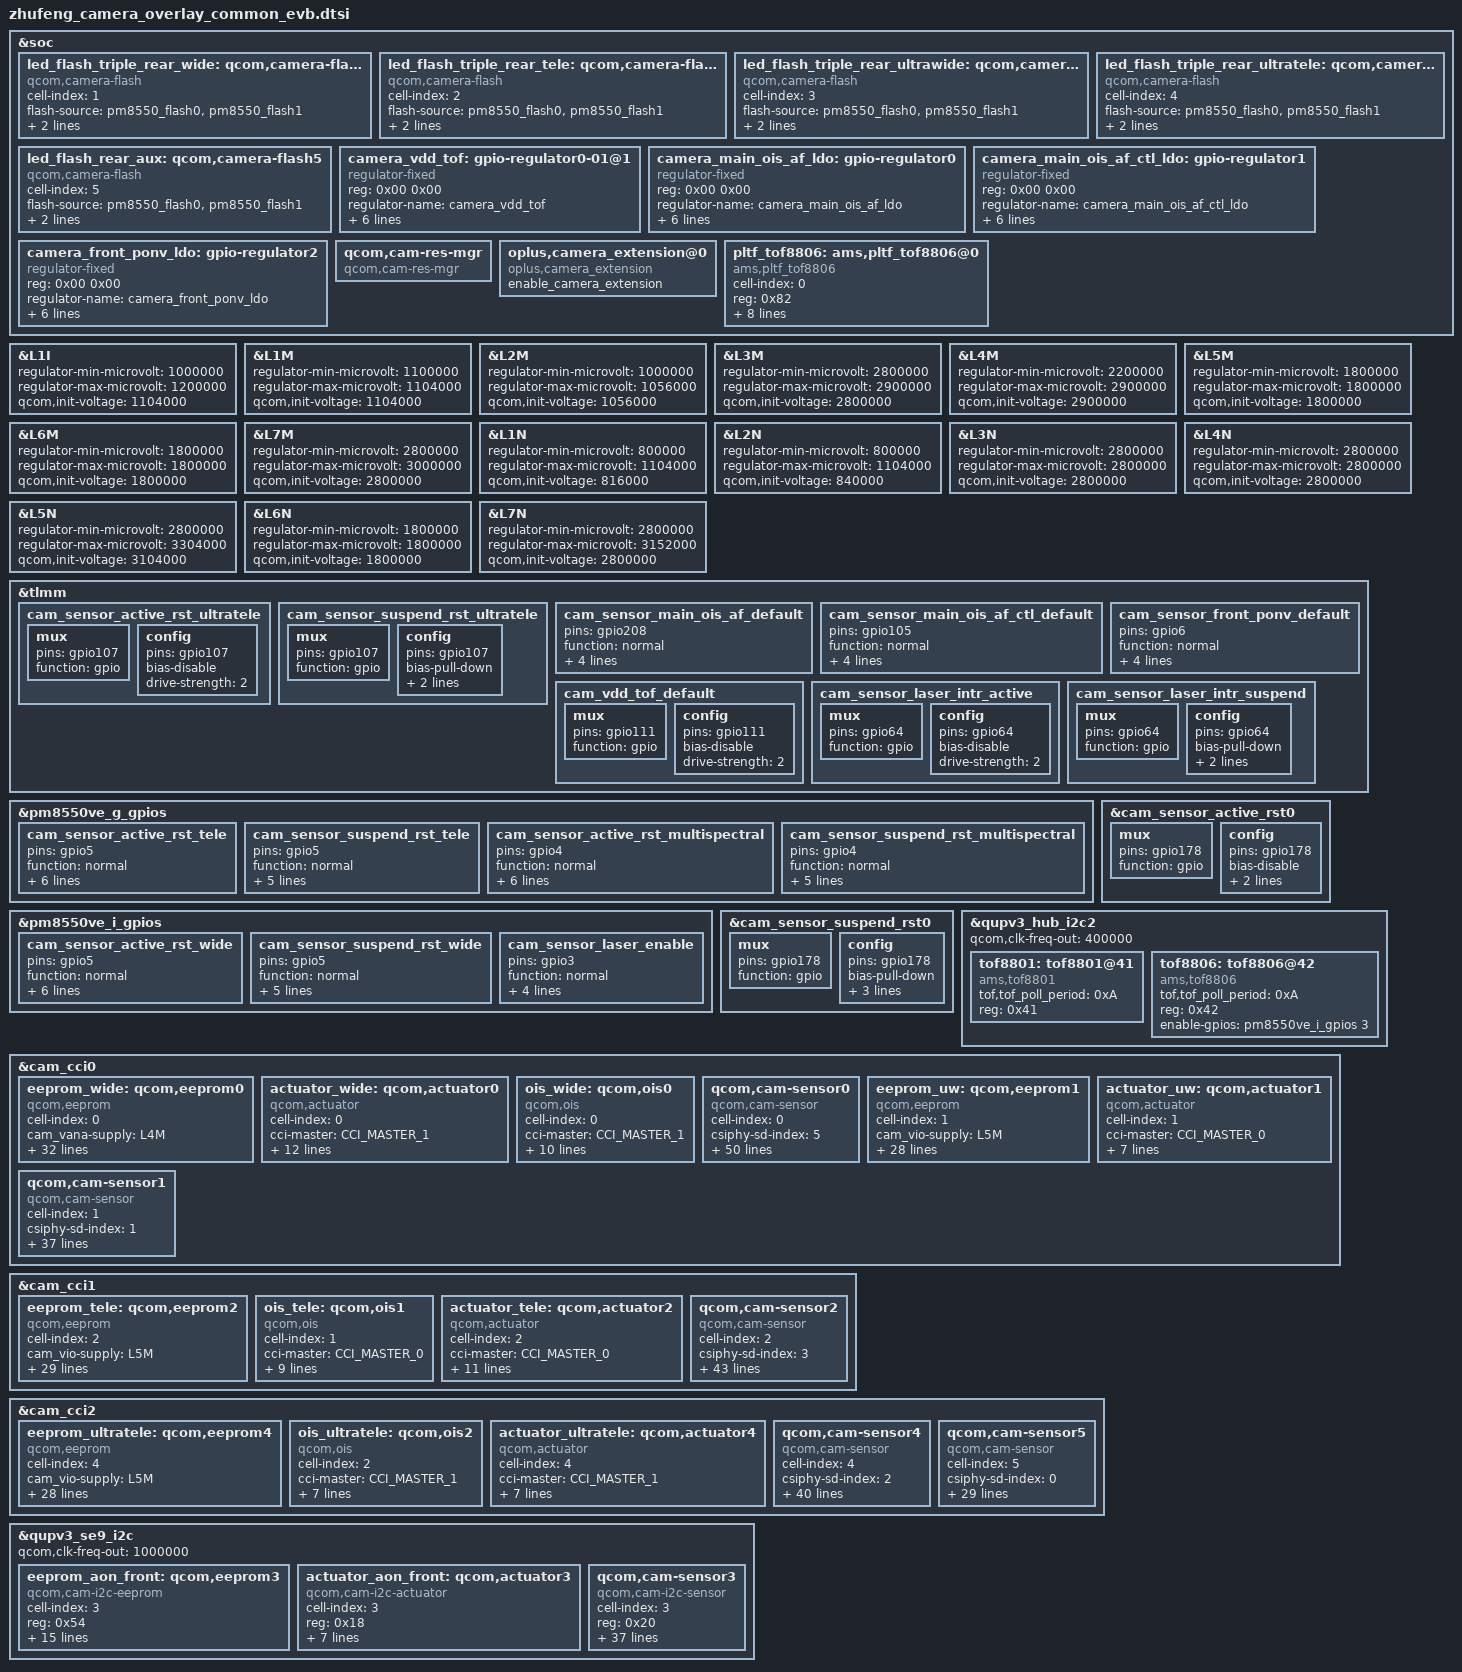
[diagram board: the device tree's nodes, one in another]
#include <dt-bindings/msm-camera.h>
#include "ftm_camera_settings.dtsi"
&soc {
	led_flash_triple_rear_wide: qcom,camera-flash1 {
		cell-index = <1>;
		compatible = "qcom,camera-flash";
		flash-source = <&pm8550_flash0 &pm8550_flash1>;
		torch-source = <&pm8550_torch0 &pm8550_torch1>;
		switch-source = <&pm8550_switch2>;
		status = "ok";
	};

	led_flash_triple_rear_tele: qcom,camera-flash2 {
		cell-index = <2>;
		compatible = "qcom,camera-flash";
		flash-source = <&pm8550_flash0 &pm8550_flash1>;
		torch-source = <&pm8550_torch0 &pm8550_torch1>;
		switch-source = <&pm8550_switch2>;
		status = "ok";
	};

	led_flash_triple_rear_ultrawide: qcom,camera-flash3 {
		cell-index = <3>;
		compatible = "qcom,camera-flash";
		flash-source = <&pm8550_flash0 &pm8550_flash1>;
		torch-source = <&pm8550_torch0 &pm8550_torch1>;
		switch-source = <&pm8550_switch2>;
		status = "ok";
	};

	led_flash_triple_rear_ultratele: qcom,camera-flash4 {
		cell-index = <4>;
		compatible = "qcom,camera-flash";
		flash-source = <&pm8550_flash0 &pm8550_flash1>;
		torch-source = <&pm8550_torch0 &pm8550_torch1>;
		switch-source = <&pm8550_switch2>;
		status = "ok";
	};

	led_flash_rear_aux: qcom,camera-flash5 {
		cell-index = <5>;
		compatible = "qcom,camera-flash";
		flash-source = <&pm8550_flash0 &pm8550_flash1>;
		torch-source = <&pm8550_torch0 &pm8550_torch1>;
		switch-source = <&pm8550_switch2>;
		status = "ok";
	};

	camera_vdd_tof: gpio-regulator0-01@1 {
		compatible = "regulator-fixed";
		reg = <0x00 0x00>;
		regulator-name = "camera_vdd_tof";
		regulator-min-microvolt = <3000000>;
		regulator-max-microvolt = <3000000>;
		regulator-enable-ramp-delay = <135>;
		enable-active-high;
		gpio = <&tlmm 111 0>;
		pinctrl-names = "default";
		pinctrl-0 = <&cam_vdd_tof_default>;
    };

	camera_main_ois_af_ldo: gpio-regulator0 {
		compatible = "regulator-fixed";
		reg = <0x00 0x00>;
		regulator-name = "camera_main_ois_af_ldo";
		regulator-min-microvolt = <3152000>;
		regulator-max-microvolt = <3152000>;
		regulator-enable-ramp-delay = <135>;
		enable-active-high;
		gpio = <&tlmm 208 0>;
		pinctrl-names = "default";
		pinctrl-0 = <&cam_sensor_main_ois_af_default>;
	};

	camera_main_ois_af_ctl_ldo: gpio-regulator1 {
		compatible = "regulator-fixed";
		reg = <0x00 0x00>;
		regulator-name = "camera_main_ois_af_ctl_ldo";
		regulator-min-microvolt = <3152000>;
		regulator-max-microvolt = <3152000>;
		regulator-enable-ramp-delay = <135>;
		enable-active-high;
		gpio = <&tlmm 105 0>;
		pinctrl-names = "default";
		pinctrl-0 = <&cam_sensor_main_ois_af_ctl_default>;
	};

	camera_front_ponv_ldo: gpio-regulator2 {
		compatible = "regulator-fixed";
		reg = <0x00 0x00>;
		regulator-name = "camera_front_ponv_ldo";
		regulator-min-microvolt = <2800000>;
		regulator-max-microvolt = <2800000>;
		regulator-enable-ramp-delay = <135>;
		enable-active-high;
		gpio = <&tlmm 6 0>;
		pinctrl-names = "default";
		pinctrl-0 = <&cam_sensor_front_ponv_default>;
	};

	qcom,cam-res-mgr {
		compatible = "qcom,cam-res-mgr";
		status = "ok";
	};

	oplus,camera_extension@0 {
		compatible = "oplus,camera_extension";
		enable_camera_extension;
		status = "ok";
	};

	pltf_tof8806: ams,pltf_tof8806@0 {
		cell-index = <0>;
		reg = <0x82>;
		compatible = "ams,pltf_tof8806","ams,pltf_tof8801";
		cam_vio-supply = <&L5M>;
		cam_vana-supply = <&camera_vdd_tof>;
		regulator-names = "cam_vio", "cam_vana";
		rgltr-cntrl-support;
		rgltr-min-voltage = <1800000 3000000>;
		rgltr-max-voltage = <1800000 3000000>;
		rgltr-load-current = <600000 300000>;
		cci-master = <CCI_MASTER_1>;
		status = "ok";
	};

};

&L1I {
	regulator-min-microvolt = <1000000>;
	regulator-max-microvolt = <1200000>;
	qcom,init-voltage = <1104000>;
};

&L1M {
  regulator-min-microvolt = <1100000>;
  regulator-max-microvolt = <1104000>;
  qcom,init-voltage = <1104000>;
};

&L2M {
  regulator-min-microvolt = <1000000>;
  regulator-max-microvolt = <1056000>;
  qcom,init-voltage = <1056000>;
};

&L3M {
  regulator-min-microvolt = <2800000>;
  regulator-max-microvolt = <2900000>;
  qcom,init-voltage = <2800000>;
};

&L4M {
  regulator-min-microvolt = <2200000>;
  regulator-max-microvolt = <2900000>;
  qcom,init-voltage = <2900000>;
};

&L5M {
  regulator-min-microvolt = <1800000>;
  regulator-max-microvolt = <1800000>;
  qcom,init-voltage = <1800000>;
};

&L6M {
  regulator-min-microvolt = <1800000>;
  regulator-max-microvolt = <1800000>;
  qcom,init-voltage = <1800000>;
};

&L7M {
  regulator-min-microvolt = <2800000>;
  regulator-max-microvolt = <3000000>;
  qcom,init-voltage = <2800000>;
};

&L1N {
  regulator-min-microvolt = <800000>;
  regulator-max-microvolt = <1104000>;
  qcom,init-voltage = <816000>;
};

&L2N {
  regulator-min-microvolt = <800000>;
  regulator-max-microvolt = <1104000>;
  qcom,init-voltage = <840000>;
};

&L3N {
  regulator-min-microvolt = <2800000>;
  regulator-max-microvolt = <2800000>;
  qcom,init-voltage = <2800000>;
};

&L4N {
  regulator-min-microvolt = <2800000>;
  regulator-max-microvolt = <2800000>;
  qcom,init-voltage = <2800000>;
};

&L5N {
  regulator-min-microvolt = <2800000>;
  regulator-max-microvolt = <3304000>;
  qcom,init-voltage = <3104000>;
};

&L6N {
  regulator-min-microvolt = <1800000>;
  regulator-max-microvolt = <1800000>;
  qcom,init-voltage = <1800000>;
};

&L7N {
  regulator-min-microvolt = <2800000>;
  regulator-max-microvolt = <3152000>;
  qcom,init-voltage = <2800000>;
};

&tlmm {
	cam_sensor_active_rst_ultratele:cam_sensor_active_rst_ultratele {
		mux {
			pins = "gpio107";
			function = "gpio";
		};

		config {
			pins = "gpio107";
			bias-disable; /* No PULL */
			drive-strength = <2>; /* 2 MA */
		};
	};

	cam_sensor_suspend_rst_ultratele: cam_sensor_suspend_rst_ultratele {
		mux {
			pins = "gpio107";
			function = "gpio";
		};

		config {
			pins = "gpio107";
			bias-pull-down; /* PULL DOWN */
			drive-strength = <2>; /* 2 MA */
			output-low;
		};
	};

	cam_sensor_main_ois_af_default: cam_sensor_main_ois_af_default {
		pins = "gpio208";
		function = "normal";
		input-disable;
		output-high;
		power-source = <1>; /* 3.1V */
		qcom,drive-strength = <2>;
	};

	cam_sensor_main_ois_af_ctl_default: cam_sensor_main_ois_af_ctl_default {
		pins = "gpio105";
		function = "normal";
		input-disable;
		output-high;
		power-source = <1>; /* 3.1V */
		qcom,drive-strength = <2>;
	};

	cam_sensor_front_ponv_default: cam_sensor_front_ponv_default {
		/* PONV */
		pins = "gpio6";
		function = "normal";
		input-disable;
		output-high;
		power-source = <1>; /* 3.1V */
		qcom,drive-strength = <2>;
	};

	cam_vdd_tof_default:cam_vdd_tof_default {
		/*  VIO LDO */
		mux {
			pins = "gpio111";
			function = "gpio";
		};

		config {
			pins = "gpio111";
			bias-disable; /* No PULL */
			drive-strength = <2>; /* 2 MA */
		};
	};

	cam_sensor_laser_intr_active:cam_sensor_laser_intr_active {
		mux {
			pins = "gpio64";
			function = "gpio";
		};

		config {
			pins = "gpio64";
			bias-disable; /* No PULL */
			drive-strength = <2>; /* 2 MA */
		};
	};

	cam_sensor_laser_intr_suspend: cam_sensor_laser_intr_suspend {
		mux {
			pins = "gpio64";
			function = "gpio";
		};

		config {
			pins = "gpio64";
			bias-pull-down; /* PULL DOWN */
			drive-strength = <2>; /* 2 MA */
			output-low;
		};
	};

};

&pm8550ve_g_gpios {
	cam_sensor_active_rst_tele: cam_sensor_active_rst_tele {
		pins = "gpio5";
		function = "normal";
		input-disable;
		output-enable;
		bias-disable;
		output-low;
		power-source = <1>;
		qcom,drive-strength = <2>;
	};

	cam_sensor_suspend_rst_tele: cam_sensor_suspend_rst_tele {
		pins = "gpio5";
		function = "normal";
		input-disable;
		output-enable;
		bias-pull-down;
		power-source = <1>;
		qcom,drive-strength = <2>;
	};

	cam_sensor_active_rst_multispectral: cam_sensor_active_rst_multispectral {
		pins = "gpio4";
		function = "normal";
		input-disable;
		output-enable;
		bias-disable;
		output-low;
		power-source = <1>;
		qcom,drive-strength = <2>;
	};

	cam_sensor_suspend_rst_multispectral: cam_sensor_suspend_rst_multispectral {
		pins = "gpio4";
		function = "normal";
		input-disable;
		output-enable;
		bias-pull-down;
		power-source = <1>;
		qcom,drive-strength = <2>;
	};
};

&pm8550ve_i_gpios {
	cam_sensor_active_rst_wide: cam_sensor_active_rst_wide {
		pins = "gpio5";
		function = "normal";
		input-disable;
		output-enable;
		bias-disable;
		output-low;
		power-source = <1>;
		qcom,drive-strength = <2>;
	};

	cam_sensor_suspend_rst_wide: cam_sensor_suspend_rst_wide {
		pins = "gpio5";
		function = "normal";
		input-disable;
		output-enable;
		bias-pull-down;
		power-source = <1>;
		qcom,drive-strength = <2>;
	};

	cam_sensor_laser_enable: cam_sensor_laser_enable {
		pins = "gpio3";
		function = "normal";
		bias-disable;
		power-source = <1>;
		output-high;
		qcom,drive-strength = <2>;
	};
};

&cam_sensor_active_rst0 {
	mux {
		pins = "gpio178";
		function = "gpio";
	};

	config {
		pins = "gpio178";
		bias-disable; /* No PULL */
		drive-strength = <2>; /* 2 MA */
		qcom,apps;
	};
};

&cam_sensor_suspend_rst0 {
	mux {
		pins = "gpio178";
		function = "gpio";
	};

	config {
		pins = "gpio178";
		bias-pull-down; /* PULL DOWN */
		drive-strength = <2>; /* 2 MA */
		output-low;
		qcom,remote;
	};
};


&qupv3_hub_i2c2 {
	status = "ok";
	qcom,clk-freq-out = <400000>;
	tof8801: tof8801@41 {
		tof,tof_poll_period = <0xA>; /*poll period (100 usec)*/
		compatible ="ams,tof8801";
		reg = <0x41>;
//		pinctrl-names = "laser_default", "laser_suspend";
//		pinctrl-names = "laser_default", "laser_suspend", "default";
//		pinctrl-0 = <&cam_sensor_laser_intr_active>;
//		pinctrl-1 = <&cam_sensor_laser_intr_suspend>;
//		pinctrl-2 =  <&cam_sensor_laser_enable>;
//		interrupt-parent = <&tlmm>;
//		enable-gpios = <&pm8550ve_i_gpios 3 0>;
//		irq-gpios = <&tlmm 64 0>;
		status = "ok";
	};
	tof8806: tof8806@42 {
		tof,tof_poll_period = <0xA>; /*poll period (100 usec)*/
		compatible = "ams,tof8806";
		reg = <0x42>;
//		pinctrl-names = "laser_default", "laser_suspend";
//		pinctrl-names = "laser_default", "laser_suspend", "default";
//		pinctrl-0 = <&cam_sensor_laser_intr_active>;
//		pinctrl-1 = <&cam_sensor_laser_intr_suspend>;
//		pinctrl-2 =  <&cam_sensor_laser_enable>;
//		interrupt-parent = <&tlmm>;
		enable-gpios = <&pm8550ve_i_gpios 3 0>;
//		irq-gpios = <&tlmm 64 0>;
		status = "ok";
	};


};

&cam_cci0 {
	eeprom_wide: qcom,eeprom0 {
		cell-index = <0>;
		compatible = "qcom,eeprom";
		cam_vana-supply = <&L4M>;
		cam_v_custom1-supply = <&L6M>;
		cam_vio-supply = <&L5M>;
		cam_vdig-supply = <&L2N>;
		cam_vaf-supply = <&camera_main_ois_af_ldo>;
		cam_v_custom2-supply = <&camera_main_ois_af_ctl_ldo>;
		cam_clk-supply = <&cam_cc_titan_top_gdsc>;
		regulator-names = "cam_vio", "cam_vdig", "cam_clk", "cam_vana",
			"cam_vaf", "cam_v_custom1", "cam_v_custom2";
		rgltr-cntrl-support;
		rgltr-min-voltage = <1800000 840000 0 2900000 3152000 1800000 3152000>;
		rgltr-max-voltage = <1800000 1104000 0 2900000 3152000 1800000 3152000>;
		rgltr-load-current = <600000 1200000 0 300000 325000 300000 325000>;
		gpio-no-mux = <0>;
		pinctrl-names = "cam_default", "cam_suspend";
		pinctrl-0 = <&cam_sensor_mclk1_active
				 &cam_sensor_active_rst_wide>;
		pinctrl-1 = <&cam_sensor_mclk1_suspend
				 &cam_sensor_suspend_rst_wide>;
		gpios = <&tlmm 90 0>,
			<&pm8550ve_i_gpios 5 0>;
		gpio-reset = <1>;
		gpio-req-tbl-num = <0 1>;
		gpio-req-tbl-flags = <1 0>;
		gpio-req-tbl-label = "CAMIF_MCLK1",
					"CAM_RESET1";
		cci-master = <CCI_MASTER_1>;
		clocks = <&cambistmclkcc CAM_BIST_MCLK_CC_MCLK1_CLK>;
		clock-names = "cam_clk";
		clock-cntl-level = "nominal";
		clock-rates = <19200000>;
		status = "ok";
	};

	actuator_wide: qcom,actuator0 {
		cell-index = <0>;
		compatible = "qcom,actuator";
		cci-master = <CCI_MASTER_1>;
		cam_vio-supply = <&L5M>;
		cam_vaf-supply = <&camera_main_ois_af_ldo>;
		cam_v_custom1-supply = <&camera_main_ois_af_ctl_ldo>;
		regulator-names = "cam_vio", "cam_vaf", "cam_v_custom1";
		rgltr-cntrl-support;
		rgltr-min-voltage = <1800000 3152000 3152000>;
		rgltr-max-voltage = <1800000 3152000 3152000>;
		rgltr-load-current = <600000 325000 325000>;
		power-size-support = <3>;
		power-custom1-reg;
		status = "ok";
	};

	ois_wide: qcom,ois0 {
		cell-index = <0>;
		compatible = "qcom,ois";
		cci-master = <CCI_MASTER_1>;
		cam_vio-supply = <&L5M>;
		cam_vaf-supply = <&camera_main_ois_af_ldo>;
		cam_v_custom2-supply = <&camera_main_ois_af_ctl_ldo>;
		regulator-names = "cam_vio", "cam_vaf", "cam_v_custom2";
		rgltr-cntrl-support;
		rgltr-min-voltage = <1800000 3152000 3152000>;
		rgltr-max-voltage = <1800000 3152000 3152000>;
		rgltr-load-current = <600000 325000 325000>;
		status = "ok";
	};

	// wide camera
	qcom,cam-sensor0 {
		cell-index = <0>;
		compatible = "qcom,cam-sensor";
		csiphy-sd-index = <5>;
		sensor-position-roll = <90>;
		sensor-position-pitch = <0>;
		sensor-position-yaw = <180>;
		eeprom-src = <&eeprom_wide>;
		actuator-src = <&actuator_wide>;
		ois-src = <&ois_wide>;
		led-flash-src = <&led_flash_triple_rear_wide>;
		cam_vana-supply = <&L4M>;
		cam_v_custom1-supply = <&L6M>;
		cam_vio-supply = <&L5M>;
		cam_vdig-supply = <&L2N>;
		cam_vaf-supply = <&camera_main_ois_af_ldo>;
		cam_v_custom2-supply = <&camera_main_ois_af_ctl_ldo>;
		cam_clk-supply = <&cam_cc_titan_top_gdsc>;
		regulator-names = "cam_vio", "cam_vdig", "cam_clk", "cam_vana",
			"cam_vaf", "cam_v_custom1", "cam_v_custom2";
		rgltr-cntrl-support;
		rgltr-min-voltage = <1800000 840000 0 2900000 3152000 1800000 3152000>;
		rgltr-max-voltage = <1800000 1104000 0 2900000 3152000 1800000 3152000>;
		rgltr-load-current = <600000 1200000 0 300000 325000 300000 325000>;
		gpio-no-mux = <0>;
		pinctrl-names = "cam_default", "cam_suspend";
		pinctrl-0 = <&cam_sensor_mclk1_active
				&cam_sensor_active_rst_wide>;
		pinctrl-1 = <&cam_sensor_mclk1_suspend
				&cam_sensor_suspend_rst_wide>;
		gpios = <&tlmm 90 0>,
			<&pm8550ve_i_gpios 5 0>;
		gpio-reset = <1>;
		gpio-req-tbl-num = <0 1>;
		gpio-req-tbl-flags = <1 0>;
		gpio-req-tbl-label = "CAMIF_MCLK1",
					"CAM_RESET1";
		cci-master = <CCI_MASTER_1>;
		clocks = <&cambistmclkcc CAM_BIST_MCLK_CC_MCLK1_CLK>;
		clock-names = "cam_clk";
		clock-cntl-level = "nominal";
		clock-rates = <19200000>;
		is-support-laser = <1>;
		enable_qsc_write_in_advance = <1>;
		qsc_reg_addr = <0x24C0>;
		eeprom_slave_addr = <0xA2>;
		qsc_data_size = <2304>;
		write_qsc_addr = <0x5800>;
        ftm_setting_compatible = <'R' 0x0016 2 2 0xA18A>;
		status = "ok";
		vsync_enable_reg_addr = <0x3051>;
		vsync_enable = <1>;
		vsync_disable = <0>;
	};

	eeprom_uw: qcom,eeprom1 {
		cell-index = <1>;
		compatible = "qcom,eeprom";
		cam_vio-supply = <&L5M>;
		cam_vdig-supply = <&L1I>;
		cam_clk-supply = <&cam_cc_titan_top_gdsc>;
		cam_vana-supply = <&L3M>;
		cam_vaf-supply = <&L7M>;
		regulator-names = "cam_vio", "cam_vdig","cam_clk", "cam_vana", "cam_vaf";
		rgltr-cntrl-support;
		rgltr-min-voltage = <1800000 1104000 0 2800000 2800000>;
		rgltr-max-voltage = <1800000 1200000 0 2900000 3000000>;
		rgltr-load-current = <600000 1200000 0 300000 600000>;
		gpio-no-mux = <0>;
		pinctrl-names = "cam_default", "cam_suspend";
		pinctrl-0 = <&cam_sensor_mclk0_active
				&cam_sensor_active_rst0>;
		pinctrl-1 = <&cam_sensor_mclk0_suspend
				&cam_sensor_suspend_rst0>;
		gpios = <&tlmm 89 0>,
			<&tlmm 178 0>;
		gpio-reset = <1>;
		gpio-req-tbl-num = <0 1>;
		gpio-req-tbl-flags = <1 0>;
		gpio-req-tbl-label = "CAMIF_MCLK0",
					"CAM_RESET0";
		cci-master = <CCI_MASTER_0>;
		clocks = <&cambistmclkcc CAM_BIST_MCLK_CC_MCLK0_CLK>;
		clock-names = "cam_clk";
		clock-cntl-level = "nominal";
		clock-rates = <19200000>;
		status = "ok";
	};

	actuator_uw: qcom,actuator1 {
		cell-index = <1>;
		compatible = "qcom,actuator";
		cci-master = <CCI_MASTER_0>;
		cam_vio-supply = <&L5M>;
		cam_vaf-supply = <&L7M>;
		regulator-names = "cam_vio", "cam_vaf";
		rgltr-cntrl-support;
		rgltr-min-voltage = <1800000 2800000>;
		rgltr-max-voltage = <1800000 3000000>;
		rgltr-load-current = <600000 600000>;
		status = "ok";
	};

	// ultrawide camera
	qcom,cam-sensor1 {
		cell-index = <1>;
		compatible = "qcom,cam-sensor";
		csiphy-sd-index = <1>;
		sensor-position-roll = <90>;
		sensor-position-pitch = <0>;
		sensor-position-yaw = <180>;
		eeprom-src = <&eeprom_uw>;
		actuator-src = <&actuator_uw>;
		led-flash-src = <&led_flash_triple_rear_ultrawide>;
		cam_vio-supply = <&L5M>;
		cam_vdig-supply = <&L1I>;
		cam_clk-supply = <&cam_cc_titan_top_gdsc>;
		cam_vana-supply = <&L3M>;
		cam_vaf-supply = <&L7M>;
		regulator-names = "cam_vio", "cam_vdig","cam_clk", "cam_vana", "cam_vaf";
		rgltr-cntrl-support;
		rgltr-min-voltage = <1800000 1104000 0 2800000 2800000>;
		rgltr-max-voltage = <1800000 1200000 0 2900000 3000000>;
		rgltr-load-current = <600000 1200000 0 300000 600000>;
		gpio-no-mux = <0>;
		pinctrl-names = "cam_default", "cam_suspend";
		pinctrl-0 = <&cam_sensor_mclk0_active
				&cam_sensor_active_rst0>;
		pinctrl-1 = <&cam_sensor_mclk0_suspend
				&cam_sensor_suspend_rst0>;
		gpios = <&tlmm 89 0>,
			<&tlmm 178 0>;
		gpio-reset = <1>;
		gpio-req-tbl-num = <0 1>;
		gpio-req-tbl-flags = <1 0>;
		gpio-req-tbl-label = "CAMIF_MCLK0",
					"CAM_RESET0";
		cci-master = <CCI_MASTER_0>;
		clocks = <&cambistmclkcc CAM_BIST_MCLK_CC_MCLK0_CLK>;
		clock-names = "cam_clk";
		clock-cntl-level = "nominal";
		clock-rates = <19200000>;
		ftm_setting_compatible = <'W' 0xFCFC 2 2 0x4000  'R' 0x0000 2 2 0x38E5>; // expect camera_0000_38E5
		status = "ok";
	};
};

&cam_cci1 {
	// tele camera
	eeprom_tele: qcom,eeprom2 {
		cell-index = <2>;
		compatible = "qcom,eeprom";
		cam_vio-supply = <&L5M>;
		cam_vdig-supply = <&L2M>;
		cam_clk-supply = <&cam_cc_titan_top_gdsc>;
		cam_vana-supply = <&L4N>;
		cam_v_custom1-supply = <&L6N>;
		cam_vaf-supply = <&L16B>;
		regulator-names = "cam_vio", "cam_vdig", "cam_clk",
			"cam_vana", "cam_vaf", "cam_v_custom1";
		rgltr-cntrl-support;
		rgltr-min-voltage = <1800000 1056000 0 2800000 2800000 1800000>;
		rgltr-max-voltage = <1800000 1056000 0 2800000 2800000 1800000>;
		rgltr-load-current = <600000 1200000 0 300000 15000 300000>;
		gpio-no-mux = <0>;
		pinctrl-names = "cam_default", "cam_suspend";
		pinctrl-0 = <&cam_sensor_mclk3_active
				 &cam_sensor_active_rst_tele>;
		pinctrl-1 = <&cam_sensor_mclk3_suspend
				 &cam_sensor_suspend_rst_tele>;
		gpios = <&tlmm 92 0>,
			<&pm8550ve_g_gpios 5 0>;
		gpio-reset = <1>;
		gpio-req-tbl-num = <0 1>;
		gpio-req-tbl-flags = <1 0>;
		gpio-req-tbl-label = "CAMIF_MCLK3",
					"CAM_RESET3";
		cci-master = <CCI_MASTER_0>;
		clocks = <&cambistmclkcc CAM_BIST_MCLK_CC_MCLK3_CLK>;
		clock-names = "cam_clk";
		clock-cntl-level = "nominal";
		clock-rates = <19200000>;
		status = "ok";
	};

	ois_tele: qcom,ois1 {
		cell-index = <1>;
		compatible = "qcom,ois";
		cci-master = <CCI_MASTER_0>;
		cam_vio-supply = <&L5M>;
		cam_vaf-supply = <&L16B>;
		cam_v_custom1-supply = <&L7N>;
		regulator-names = "cam_vio", "cam_vaf", "cam_v_custom1";
		rgltr-cntrl-support;
		rgltr-min-voltage = <1800000 2800000 3152000>;
		rgltr-max-voltage = <1800000 2800000 3152000>;
		rgltr-load-current = <600000 150000 600000>;
		status = "ok";
	};

	actuator_tele: qcom,actuator2 {
		cell-index = <2>;
		compatible = "qcom,actuator";
		cci-master = <CCI_MASTER_0>;
		cam_vio-supply = <&L5M>;
		cam_vaf-supply = <&L16B>;
		cam_v_custom1-supply = <&L7N>;
		regulator-names = "cam_vio", "cam_vaf", "cam_v_custom1";
		rgltr-cntrl-support;
		rgltr-min-voltage = <1800000 2800000 3152000>;
		rgltr-max-voltage = <1800000 2800000 3152000>;
		rgltr-load-current = <600000 150000 600000>;
		power-size-support = <3>;
		power-custom1-reg;
		status = "ok";
	};

	qcom,cam-sensor2 {
		cell-index = <2>;
		compatible = "qcom,cam-sensor";
		csiphy-sd-index = <3>;
		sensor-position-roll = <90>;
		sensor-position-pitch = <0>;
		sensor-position-yaw = <180>;
		eeprom-src = <&eeprom_tele>;
		actuator-src = <&actuator_tele>;
		ois-src = <&ois_tele>;
		led-flash-src = <&led_flash_triple_rear_tele>;
		cam_vio-supply = <&L5M>;
		cam_vdig-supply = <&L2M>;
		cam_clk-supply = <&cam_cc_titan_top_gdsc>;
		cam_vana-supply = <&L4N>;
		cam_v_custom1-supply = <&L6N>;
		cam_v_custom2-supply = <&L7N>;
		cam_vaf-supply = <&L16B>;
		regulator-names = "cam_vio", "cam_vdig", "cam_clk",
			"cam_vana", "cam_vaf", "cam_v_custom1", "cam_v_custom2";
		rgltr-cntrl-support;
		rgltr-min-voltage = <1800000 1056000 0 2800000 2800000 1800000 3152000>;
		rgltr-max-voltage = <1800000 1056000 0 2800000 2800000 1800000 3152000>;
		rgltr-load-current = <600000 1200000 0 300000 15000 300000 600000>;
		gpio-no-mux = <0>;
		pinctrl-names = "cam_default", "cam_suspend";
		pinctrl-0 = <&cam_sensor_mclk3_active
				 &cam_sensor_active_rst_tele>;
		pinctrl-1 = <&cam_sensor_mclk3_suspend
				 &cam_sensor_suspend_rst_tele>;
		gpios = <&tlmm 92 0>,
			<&pm8550ve_g_gpios 5 0>;
		gpio-reset = <1>;
		gpio-req-tbl-num = <0 1>;
		gpio-req-tbl-flags = <1 0>;
		gpio-req-tbl-label = "CAMIF_MCLK3",
					"CAM_RESET3";
		cci-master = <CCI_MASTER_0>;
		clocks = <&cambistmclkcc CAM_BIST_MCLK_CC_MCLK3_CLK>;
		clock-names = "cam_clk";
		clock-cntl-level = "nominal";
		clock-rates = <19200000>;
		ftm_setting_compatible = <'R' 0x0016 2 2 0x0906>; // expect camera_0006_0906
		status = "ok";
		vsync_enable_reg_addr = <0x3051>;
		vsync_enable = <1>;
		vsync_disable = <0>;
	};
};

&cam_cci2 {
	// ultratele camera
	eeprom_ultratele: qcom,eeprom4 {
		cell-index = <4>;
		compatible = "qcom,eeprom";
		cam_vio-supply = <&L5M>;
		cam_vdig-supply = <&L1M>;
		cam_clk-supply = <&cam_cc_titan_top_gdsc>;
		cam_vana-supply = <&L3N>;
		cam_vaf-supply = <&L5N>;
		regulator-names = "cam_vio", "cam_vdig", "cam_clk",
			"cam_vana", "cam_vaf";
		rgltr-cntrl-support;
		rgltr-min-voltage = <1800000 1104000 0 2800000 3104000>;
		rgltr-max-voltage = <1800000 1104000 0 2800000 3304000>;
		rgltr-load-current = <600000 1200000 0 300000 600000>;
		gpio-no-mux = <0>;
		pinctrl-names = "cam_default", "cam_suspend";
		pinctrl-0 = <&cam_sensor_mclk2_active
				 &cam_sensor_active_rst_ultratele>;
		pinctrl-1 = <&cam_sensor_mclk2_suspend
				 &cam_sensor_suspend_rst_ultratele>;
		gpios = <&tlmm 91 0>,
			<&tlmm 107 0>;
		gpio-reset = <1>;
		gpio-req-tbl-num = <0 1>;
		gpio-req-tbl-flags = <1 0>;
		gpio-req-tbl-label = "CAMIF_MCLK2",
					"CAM_RESET2";
		cci-master = <CCI_MASTER_1>;
		clocks = <&cambistmclkcc CAM_BIST_MCLK_CC_MCLK2_CLK>;
		clock-names = "cam_clk";
		clock-cntl-level = "nominal";
		clock-rates = <19200000>;
		status = "ok";
	};

	ois_ultratele: qcom,ois2 {
		cell-index = <2>;
		compatible = "qcom,ois";
		cci-master = <CCI_MASTER_1>;
		cam_vio-supply = <&L5M>;
		cam_vaf-supply = <&L5N>;
		regulator-names = "cam_vio", "cam_vaf";
		rgltr-cntrl-support;
		rgltr-min-voltage = <1800000 3152000>;
		rgltr-max-voltage = <1800000 3152000>;
		rgltr-load-current = <600000 600000>;
		status = "ok";
	};

	actuator_ultratele: qcom,actuator4 {
		cell-index = <4>;
		compatible = "qcom,actuator";
		cci-master = <CCI_MASTER_1>;
		cam_vio-supply = <&L5M>;
		cam_vaf-supply = <&L5N>;
		regulator-names = "cam_vio", "cam_vaf";
		rgltr-cntrl-support;
		rgltr-min-voltage = <1800000 3104000>;
		rgltr-max-voltage = <1800000 3304000>;
		rgltr-load-current = <600000 600000>;
		status = "ok";
	};

	qcom,cam-sensor4 {
		cell-index = <4>;
		compatible = "qcom,cam-sensor";
		csiphy-sd-index = <2>;
		sensor-position-roll = <90>;
		sensor-position-pitch = <0>;
		sensor-position-yaw = <180>;
		eeprom-src = <&eeprom_ultratele>;
		actuator-src = <&actuator_ultratele>;
		ois-src = <&ois_ultratele>;
		led-flash-src = <&led_flash_triple_rear_ultratele>;
		cam_vio-supply = <&L5M>;
		cam_vdig-supply = <&L1M>;
		cam_clk-supply = <&cam_cc_titan_top_gdsc>;
		cam_vana-supply = <&L3N>;
		cam_vaf-supply = <&L5N>;
		regulator-names = "cam_vio", "cam_vdig", "cam_clk",
			"cam_vana", "cam_vaf";
		rgltr-cntrl-support;
		rgltr-min-voltage = <1800000 1104000 0 2800000 3104000>;
		rgltr-max-voltage = <1800000 1104000 0 2800000 3304000>;
		rgltr-load-current = <600000 1200000 0 300000 600000>;
		gpio-no-mux = <0>;
		pinctrl-names = "cam_default", "cam_suspend";
		pinctrl-0 = <&cam_sensor_mclk2_active
				 &cam_sensor_active_rst_ultratele>;
		pinctrl-1 = <&cam_sensor_mclk2_suspend
				 &cam_sensor_suspend_rst_ultratele>;
		gpios = <&tlmm 91 0>,
			<&tlmm 107 0>;
		gpio-reset = <1>;
		gpio-req-tbl-num = <0 1>;
		gpio-req-tbl-flags = <1 0>;
		gpio-req-tbl-label = "CAMIF_MCLK2",
					"CAM_RESET2";
		cci-master = <CCI_MASTER_1>;
		clocks = <&cambistmclkcc CAM_BIST_MCLK_CC_MCLK2_CLK>;
		clock-names = "cam_clk";
		clock-cntl-level = "nominal";
		clock-rates = <19200000>;
		ftm_setting_compatible = <'R' 0x0016 2 2 0x8202>; // expect camera_0016_8202
		status = "ok";
		vsync_enable_reg_addr = <0x3051>;
		vsync_enable = <1>;
		vsync_disable = <0>;
	};

	//multispectral sensor
	qcom,cam-sensor5 {
		cell-index = <5>;
		compatible = "qcom,cam-sensor";
		csiphy-sd-index = <0>;
		sensor-position-roll = <90>;
		sensor-position-pitch = <0>;
		sensor-position-yaw = <180>;
		cam_vana-supply = <&L3M>;
		cam_vio-supply = <&L5M>;
		cam_clk-supply = <&cam_cc_titan_top_gdsc>;
		regulator-names = "cam_vana", "cam_vio", "cam_clk";
		rgltr-cntrl-support;
		rgltr-min-voltage = <2800000 1800000 0>;
		rgltr-max-voltage = <2900000 1800000 0>;
		rgltr-load-current = <300000 600000 0>;
		gpio-no-mux = <0>;
		pinctrl-names = "cam_default", "cam_suspend";
		pinctrl-0 = <&cam_sensor_mclk5_active
				 &cam_sensor_active_rst_multispectral>;
		pinctrl-1 = <&cam_sensor_mclk5_suspend
				 &cam_sensor_suspend_rst_multispectral>;
		gpios = <&tlmm 94 0>,
			<&pm8550ve_g_gpios 4 0>;
		gpio-reset = <1>;
		gpio-req-tbl-num = <0 1>;
		gpio-req-tbl-flags = <1 0>;
		gpio-req-tbl-label = "CAMIF_MCLK5",
					"CAM_RESET5";
		cci-master = <CCI_MASTER_0>;
		clocks = <&cambistmclkcc CAM_BIST_MCLK_CC_MCLK5_CLK>;
		clock-names = "cam_clk";
		clock-cntl-level = "nominal";
		clock-rates = <24000000>;
		ftm_setting_compatible = <'R' 0x03 1 1 0x2b>;
		reg_otp_compatible = <'W' 0xFD 1 1 0x06 'R' 0x00 1 1 16>;
		status = "ok";
	};
};

&qupv3_se9_i2c {
	status = "ok";
	// qcom,high-perf;
	qcom,clk-freq-out = <1000000>;
	// qcom,pm-ctrl-client;

	eeprom_aon_front: qcom,eeprom3 {
		cell-index = <3>;
		reg = <0x54>; //slave address >> 1
		compatible = "qcom,cam-i2c-eeprom";
		cam_vio-supply = <&L5M>;
		cam_vdig-supply = <&L1N>;
		cam_clk-supply = <&cam_cc_titan_top_gdsc>;
		cam_vana-supply = <&L3M>;
		cam_vaf-supply = <&L7M>;
		cam_v_custom1-supply = <&camera_front_ponv_ldo>;
		regulator-names = "cam_vio", "cam_vdig","cam_clk", "cam_vana", "cam_vaf", "cam_v_custom1";
		rgltr-cntrl-support;
		rgltr-min-voltage = <1800000 816000 0 2900000 2800000 2800000>;
		rgltr-max-voltage = <1800000 1104000 0 2900000 3000000 2800000>;
		rgltr-load-current = <600000 1200000 0 300000 600000 300000>;
		// gpio-no-mux = <0>;
		// pinctrl-names = "cam_default", "cam_suspend";
		// pinctrl-0 = <&cam_sensor_mclk4_active
		// 		 &cam_sensor_active_rst4>;
		// pinctrl-1 = <&cam_sensor_mclk4_suspend
		// 		 &cam_sensor_suspend_rst4>;
		// gpios = <&tlmm 93 0>,
		// 	<&tlmm 7 0>;
		// gpio-reset = <1>;
		// gpio-req-tbl-num = <0 1>;
		// gpio-req-tbl-flags = <1 0>;
		// gpio-req-tbl-label = "CAMIF_MCLK4",
		// 			"CAM_RESET4";
		// clocks = <&cambistmclkcc CAM_BIST_MCLK_CC_MCLK4_CLK>;
		// clock-names = "cam_clk";
		// clock-cntl-level = "nominal";
		// clock-rates = <19200000>;
		status = "ok";
	};

	actuator_aon_front: qcom,actuator3 {
		cell-index = <3>;
		reg = <0x18>;
		compatible = "qcom,cam-i2c-actuator";
		cam_vio-supply = <&L5M>;
		cam_vaf-supply = <&L7M>;
		regulator-names = "cam_vio", "cam_vaf";
		rgltr-cntrl-support;
		rgltr-min-voltage = <1800000 2800000>;
		rgltr-max-voltage = <1800000 3000000>;
		rgltr-load-current = <600000 600000>;
		status = "ok";
	};

	// front camera
	qcom,cam-sensor3 {
		cell-index = <3>;
		reg = <0x20>;
		compatible = "qcom,cam-i2c-sensor";
		csiphy-sd-index = <4>;
		sensor-position-roll = <270>;
		sensor-position-pitch = <0>;
		sensor-position-yaw = <180>;
		eeprom-src = <&eeprom_aon_front>;
		actuator-src = <&actuator_aon_front>;
		cam_vio-supply = <&L5M>;
		cam_vdig-supply = <&L1N>;
		cam_clk-supply = <&cam_cc_titan_top_gdsc>;
		cam_vana-supply = <&L3M>;
		cam_vaf-supply = <&L7M>;
		cam_v_custom1-supply = <&camera_front_ponv_ldo>;
		regulator-names = "cam_vio", "cam_vdig","cam_clk", "cam_vana", "cam_vaf", "cam_v_custom1";
		rgltr-cntrl-support;
		aon-camera-id = <AON_CAM1>;
		rgltr-min-voltage = <1800000 816000 0 2900000 2800000 2800000>;
		rgltr-max-voltage = <1800000 1104000 0 2900000 3000000 2800000>;
		rgltr-load-current = <600000 1200000 0 300000 600000 300000>;
		gpio-no-mux = <0>;
		pinctrl-names = "cam_default", "cam_suspend";
		pinctrl-0 = <&cam_sensor_mclk4_active
				&cam_sensor_active_rst4>;
		pinctrl-1 = <&cam_sensor_mclk4_suspend
				&cam_sensor_suspend_rst4>;
		gpios = <&tlmm 93 0>,
			<&tlmm 7 0>;
		gpio-reset = <1>;
		gpio-req-tbl-num = <0 1>;
		gpio-req-tbl-flags = <1 0>;
		gpio-req-tbl-label = "CAMIF_MCLK4",
					"CAM_RESET4";
		clocks = <&cambistmclkcc CAM_BIST_MCLK_CC_MCLK4_CLK>;
		clock-names = "cam_clk";
		clock-cntl-level = "nominal";
		clock-rates = <19200000>;
		ftm_setting_compatible = <'R' 0x0016 2 2 0x0809>;
		status = "ok";
	};
};

